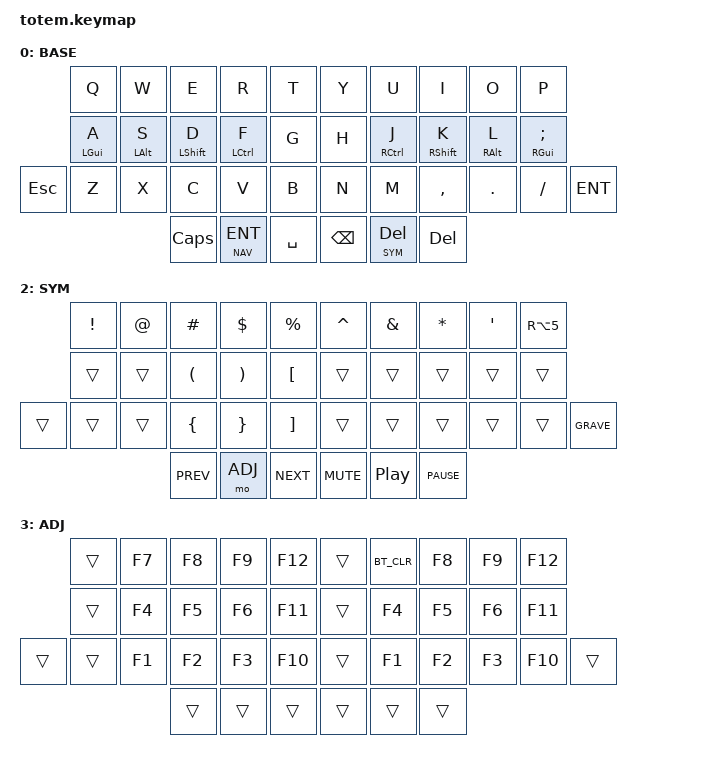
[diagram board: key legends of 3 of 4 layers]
//
//                                                        ▀▀▀▀▀     ▀▀▀▀▀          ▀▀█▀▀
//                                                        ▄▀▀▀▄  ▄  ▄▀▀▀▄  ▄  ▄▀▀▀▄  █  ▄▀▀▀▄
//                                                        █   █  █  █   █  █  █   █  █  █   █
//                                                         ▀▀▀   █   ▀▀▀   █   ▀▀▀   ▀   ▀▀▀
//                                                               █      ▄▄▄█▄▄▄    █   █  
//                                                               ▀      █  █  █     █▄█
//                                                             ▀▀▀▀▀    █  █  █      ▀
//                                                                      ▀  ▀  ▀
//
// ▄▄▄▄▄▄▄▄▄▄▄▄▄▄▄▄▄▄▄▄▄▄▄▄▄▄▄▄▄▄▄▄▄▄▄▄▄▄▄▄▄▄▄▄▄▄▄▄▄▄▄▄▄▄▄▄▄▄▄▄▄▄▄▄▄▄▄▄▄▄▄▄▄▄▄▄▄▄▄▄▄▄▄▄▄▄▄▄▄▄▄▄▄▄▄▄▄▄▄▄▄▄▄▄▄▄▄▄▄▄▄▄▄▄▄▄▄▄▄▄▄▄▄▄▄▄▄▄▄▄▄▄▄▄▄▄▄▄▄▄▄▄▄▄▄▄▄▄▄
       

#include <behaviors.dtsi>
#include <dt-bindings/zmk/keys.h>
#include <dt-bindings/zmk/bt.h>
#include <dt-bindings/zmk/outputs.h>

#define BASE 0
#define NAV  1
#define SYM  2
#define ADJ  3

&mt {
  quick-tap-ms = <100>;
  global-quick-tap;
  flavor = "tap-preferred";
  tapping-term-ms = <170>;
};

/ {
    combos {
            compatible = "zmk,combos";
            combo_esc {
                timeout-ms = <50>;
                key-positions = <0 1>;
                bindings = <&kp ESC>;
            };
    };

    macros {
        gif: gif {
            label = "giphy";
            compatible = "zmk,behavior-macro";
            #binding-cells = <0>;
            bindings
                = <&macro_press &kp LSHFT>
                , <&macro_tap &kp N2>
                , <&macro_release &kp LSHFT>
                , <&macro_tap &kp G &kp I &kp F>
                ;
        };
    };

        keymap {
                compatible = "zmk,keymap";
// ▄▄▄▄▄▄▄▄▄▄▄▄▄▄▄▄▄▄▄▄▄▄▄▄▄▄▄▄▄▄▄▄▄▄▄▄▄▄▄▄▄▄▄▄▄▄▄▄▄▄▄▄▄▄▄▄▄▄▄▄▄▄▄▄▄▄▄▄▄▄▄▄▄▄▄▄▄▄▄▄▄▄▄▄▄▄▄▄▄▄▄▄▄▄▄▄▄▄▄▄▄▄▄▄▄▄▄▄▄▄▄▄▄▄▄▄▄▄▄▄▄▄▄▄▄▄▄▄▄▄▄▄▄▄▄▄▄▄▄▄▄▄▄▄▄▄▄▄▄

                base_layer {
// ┏━━━━━━━━━━━━━━━━━━━━━━━━━━━━━━━━━━━━━━━┓
label= "BASE"                              ;
// ┗━━━━━━━━━━━━━━━━━━━━━━━━━━━━━━━━━━━━━━━┛
//             ┏━━━━━━━━━━━┳━━━━━━━━━━━┳━━━━━━━━━━━┳━━━━━━━━━━━┳━━━━━━━━━━━┓   ┏━━━━━━━━━━━┳━━━━━━━━━━━┳━━━━━━━━━━━┳━━━━━━━━━━━┳━━━━━━━━━━━┓
//             ┃     Q     ┃     W     ┃     E     ┃     R     ┃     T     ┃   ┃     Y     ┃     U     ┃     I     ┃     O     ┃     P     ┃
//             ┣━━━━━━━━━━━╋━━━━━━━━━━━╋━━━━━━━━━━━╋━━━━━━━━━━━╋━━━━━━━━━━━┫   ┣━━━━━━━━━━━╋━━━━━━━━━━━╋━━━━━━━━━━━╋━━━━━━━━━━━╋━━━━━━━━━━━┫
//             ┃     A     ┃     S     ┃     D     ┃     F     ┃     G     ┃   ┃     H     ┃     J     ┃     K     ┃     L     ┃     ;     ┃
// ┏━━━━━━━━━━━╋━━━━━━━━━━━╋━━━━━━━━━━━╋━━━━━━━━━━━╋━━━━━━━━━━━╋━━━━━━━━━━━┫   ┣━━━━━━━━━━━╋━━━━━━━━━━━╋━━━━━━━━━━━╋━━━━━━━━━━━╋━━━━━━━━━━━╋━━━━━━━━━━━┓
// ┃    ESC    ┃     Z     ┃     X     ┃     C     ┃     V     ┃     B     ┃   ┃     N     ┃     M     ┃     ,     ┃     .     ┃     /     ┃     '     ┃
// ┗━━━━━━━━━━━┻━━━━━━━━━━━┻━━━━━━━━━━━╋━━━━━━━━━━━╋━━━━━━━━━━━╋━━━━━━━━━━━┫   ┣━━━━━━━━━━━╋━━━━━━━━━━━╋━━━━━━━━━━━╋━━━━━━━━━━━┻━━━━━━━━━━━┻━━━━━━━━━━━┛
//                                     ┃    CAPS   ┃  ENT/NAV  ┃    SPC    ┃   ┃    BSPC   ┃ DEL/SYM   ┃   PSCRN   ┃
//                                     ┗━━━━━━━━━━━┻━━━━━━━━━━━┻━━━━━━━━━━━┛   ┗━━━━━━━━━━━┻━━━━━━━━━━━┻━━━━━━━━━━━┛
 bindings = <
// ╷           ╷           ╷           ╷           ╷           ╷           ╷   ╷           ╷           ╷           ╷           ╷           ╷           ╷

                &kp Q       &kp W       &kp E       &kp R       &kp T           &kp Y       &kp U       &kp I       &kp O       &kp P
                &mt LGUI A  &mt LALT S  &mt LSHFT D &mt LCTRL F &kp G           &kp H       &mt RCTRL J &mt RSHFT K &mt RALT L  &mt RGUI SEMI
    &kp ESC     &kp Z       &kp X       &kp C       &kp V       &kp B           &kp N       &kp M       &kp COMMA   &kp DOT     &kp FSLH    &kp ENT
                                        &kp CAPS    &lt NAV ENT &kp SPACE       &kp BSPC    &lt SYM DEL &kp DEL
                        >;
                };

// ▄▄▄▄▄▄▄▄▄▄▄▄▄▄▄▄▄▄▄▄▄▄▄▄▄▄▄▄▄▄▄▄▄▄▄▄▄▄▄▄▄▄▄▄▄▄▄▄▄▄▄▄▄▄▄▄▄▄▄▄▄▄▄▄▄▄▄▄▄▄▄▄▄▄▄▄▄▄▄▄▄▄▄▄▄▄▄▄▄▄▄▄▄▄▄▄▄▄▄▄▄▄▄▄▄▄▄▄▄▄▄▄▄▄▄▄▄▄▄▄▄▄▄▄▄▄▄▄▄▄▄▄▄▄▄▄▄▄▄▄▄▄▄▄▄▄▄▄▄


                nav_layer {
// ┏━━━━━━━━━━━━━━━━━━━━━━━━━━━━━━━━━━━━━━━┓
label= "NAVI"                              ;
// ┗━━━━━━━━━━━━━━━━━━━━━━━━━━━━━━━━━━━━━━━┛

//             ┏━━━━━━━━━━━┳━━━━━━━━━━━┳━━━━━━━━━━━┳━━━━━━━━━━━┳━━━━━━━━━━━┓   ┏━━━━━━━━━━━┳━━━━━━━━━━━┳━━━━━━━━━━━┳━━━━━━━━━━━┳━━━━━━━━━━━┓
//             ┃     /     ┃     7     ┃     8     ┃     9     ┃     +     ┃   ┃   HOME    ┃  P DOWN   ┃   P UP    ┃    END    ┃           ┃
//             ┣━━━━━━━━━━━╋━━━━━━━━━━━╋━━━━━━━━━━━╋━━━━━━━━━━━╋━━━━━━━━━━━┫   ┣━━━━━━━━━━━╋━━━━━━━━━━━╋━━━━━━━━━━━╋━━━━━━━━━━━╋━━━━━━━━━━━┫
//             ┃     .     ┃     4     ┃     5     ┃     6     ┃     -     ┃   ┃   LEFT    ┃    DOWN   ┃     UP    ┃   RIGHT   ┃           ┃
// ┏━━━━━━━━━━━╋━━━━━━━━━━━╋━━━━━━━━━━━╋━━━━━━━━━━━╋━━━━━━━━━━━╋━━━━━━━━━━━┫   ┣━━━━━━━━━━━╋━━━━━━━━━━━╋━━━━━━━━━━━╋━━━━━━━━━━━╋━━━━━━━━━━━╋━━━━━━━━━━━┓
// ┃     =     ┃     0     ┃     1     ┃     2     ┃     3     ┃     *     ┃   ┃  RC(LEFT) ┃  RC(DOWN) ┃  RC(UP)   ┃ RC(RIGHT) ┃           ┃           ┃
// ┗━━━━━━━━━━━┻━━━━━━━━━━━┻━━━━━━━━━━━╋━━━━━━━━━━━╋━━━━━━━━━━━╋━━━━━━━━━━━┫   ┣━━━━━━━━━━━╋━━━━━━━━━━━╋━━━━━━━━━━━╋━━━━━━━━━━━┻━━━━━━━━━━━┻━━━━━━━━━━━┛
//                                     ┃  VOL DOWN ┃   TRANS   ┃  VOL UP   ┃   ┃           ┃    ADJ    ┃           ┃
//                                     ┗━━━━━━━━━━━┻━━━━━━━━━━━┻━━━━━━━━━━━┛   ┗━━━━━━━━━━━┻━━━━━━━━━━━┻━━━━━━━━━━━┛

 bindings = <
// ╷           ╷           ╷           ╷           ╷           ╷           ╷   ╷           ╷           ╷           ╷           ╷           ╷           ╷

                &kp FSLH    &kp N7      &kp N8      &kp N9      &kp KP_PLUS     &kp HOME    &kp PG_DN   &kp PG_UP   &kp END                
                &kp DOT     &kp N4      &kp N5      &kp N6      &kp KP_MINUS    &kp LEFT    &kp DOWN    &kp UP      &kp RIGHT              
    &kp EQUAL   &kp N0      &kp N1      &kp N2      &kp N3      &kp KP_MULTIPLY &kp RC(LEFT) &kp RC(DOWN) &kp RC(UP) &kp RC(RIGHT) &trans 
                                       &kp C_VOL_DN &trans      &kp C_VOL_UP    &trans      &mo ADJ     &trans      
                        >;
                };

// ▄▄▄▄▄▄▄▄▄▄▄▄▄▄▄▄▄▄▄▄▄▄▄▄▄▄▄▄▄▄▄▄▄▄▄▄▄▄▄▄▄▄▄▄▄▄▄▄▄▄▄▄▄▄▄▄▄▄▄▄▄▄▄▄▄▄▄▄▄▄▄▄▄▄▄▄▄▄▄▄▄▄▄▄▄▄▄▄▄▄▄▄▄▄▄▄▄▄▄▄▄▄▄▄▄▄▄▄▄▄▄▄▄▄▄▄▄▄▄▄▄▄▄▄▄▄▄▄▄▄▄▄▄▄▄▄▄▄▄▄▄▄▄▄▄▄▄▄▄


                sym_layer {
// ┏━━━━━━━━━━━━━━━━━━━━━━━━━━━━━━━━━━━━━━━┓
label= "SYM"                               ;
// ┗━━━━━━━━━━━━━━━━━━━━━━━━━━━━━━━━━━━━━━━┛    
//             ┏━━━━━━━━━━━┳━━━━━━━━━━━┳━━━━━━━━━━━┳━━━━━━━━━━━┳━━━━━━━━━━━┓   ┏━━━━━━━━━━━┳━━━━━━━━━━━┳━━━━━━━━━━━┳━━━━━━━━━━━┳━━━━━━━━━━━┓
//             ┃     !     ┃     @     ┃     #     ┃     $     ┃     %     ┃   ┃     ˆ     ┃     &     ┃     *     ┃     ~     ┃     €     ┃
//             ┣━━━━━━━━━━━╋━━━━━━━━━━━╋━━━━━━━━━━━╋━━━━━━━━━━━╋━━━━━━━━━━━┫   ┣━━━━━━━━━━━╋━━━━━━━━━━━╋━━━━━━━━━━━╋━━━━━━━━━━━╋━━━━━━━━━━━┫
//             ┃     \     ┃     -     ┃     (     ┃     )     ┃     [     ┃   ┃           ┃           ┃           ┃           ┃           ┃
// ┏━━━━━━━━━━━╋━━━━━━━━━━━╋━━━━━━━━━━━╋━━━━━━━━━━━╋━━━━━━━━━━━╋━━━━━━━━━━━┫   ┣━━━━━━━━━━━╋━━━━━━━━━━━╋━━━━━━━━━━━╋━━━━━━━━━━━╋━━━━━━━━━━━╋━━━━━━━━━━━┓
// ┃           ┃     |     ┃     _     ┃     {     ┃     }     ┃     ]     ┃   ┃           ┃           ┃           ┃           ┃           ┃     `     ┃
// ┗━━━━━━━━━━━┻━━━━━━━━━━━┻━━━━━━━━━━━╋━━━━━━━━━━━╋━━━━━━━━━━━╋━━━━━━━━━━━┫   ┣━━━━━━━━━━━╋━━━━━━━━━━━╋━━━━━━━━━━━╋━━━━━━━━━━━┻━━━━━━━━━━━┻━━━━━━━━━━━┛
//                                     ┃   PREV    ┃   ADJ     ┃   NEXT    ┃   ┃    MUTE   ┃   TRANS   ┃   PAUSE   ┃
//                                     ┗━━━━━━━━━━━┻━━━━━━━━━━━┻━━━━━━━━━━━┛   ┗━━━━━━━━━━━┻━━━━━━━━━━━┻━━━━━━━━━━━┛
 bindings = <
// ╷           ╷           ╷           ╷           ╷           ╷           ╷   ╷           ╷           ╷           ╷           ╷           ╷           ╷

                &kp EXCL    &kp AT      &kp HASH    &kp DLLR    &kp PRCNT       &kp CARET   &kp AMPS    &kp STAR   &kp SQT     &kp RA(N5)       
                &trans      &trans      &kp LPAR    &kp RPAR    &kp LBKT        &trans      &trans      &trans     &trans      &trans 
    &trans      &trans      &trans      &kp LBRC    &kp RBRC    &kp RBKT        &trans      &trans      &trans     &trans      &trans      GRAVE         
                                        &kp C_PREV  &mo ADJ     &kp C_NEXT      &kp C_MUTE  &kp C_PP    &kp C_PAUSE      
                        >;
                };

// ▄▄▄▄▄▄▄▄▄▄▄▄▄▄▄▄▄▄▄▄▄▄▄▄▄▄▄▄▄▄▄▄▄▄▄▄▄▄▄▄▄▄▄▄▄▄▄▄▄▄▄▄▄▄▄▄▄▄▄▄▄▄▄▄▄▄▄▄▄▄▄▄▄▄▄▄▄▄▄▄▄▄▄▄▄▄▄▄▄▄▄▄▄▄▄▄▄▄▄▄▄▄▄▄▄▄▄▄▄▄▄▄▄▄▄▄▄▄▄▄▄▄▄▄▄▄▄▄▄▄▄▄▄▄▄▄▄▄▄▄▄▄▄▄▄▄▄▄▄


                adjust_layer {
// ┏━━━━━━━━━━━━━━━━━━━━━━━━━━━━━━━━━━━━━━━┓
label= "ADJ"                               ;
// ┗━━━━━━━━━━━━━━━━━━━━━━━━━━━━━━━━━━━━━━━┛

//             ┏━━━━━━━━━━━┳━━━━━━━━━━━┳━━━━━━━━━━━┳━━━━━━━━━━━┳━━━━━━━━━━━┓   ┏━━━━━━━━━━━┳━━━━━━━━━━━┳━━━━━━━━━━━┳━━━━━━━━━━━┳━━━━━━━━━━━┓
//             ┃           ┃    F7     ┃    F8     ┃    F9     ┃    F12    ┃   ┃           ┃ BT CLEAR  ┃  OUT TOG  ┃  RESET    ┃ BOOTLOAD  ┃
//             ┣━━━━━━━━━━━╋━━━━━━━━━━━╋━━━━━━━━━━━╋━━━━━━━━━━━╋━━━━━━━━━━━┫   ┣━━━━━━━━━━━╋━━━━━━━━━━━╋━━━━━━━━━━━╋━━━━━━━━━━━╋━━━━━━━━━━━┫
//             ┃           ┃    F4     ┃    F5     ┃    F6     ┃    F11    ┃   ┃ BT NEXT   ┃   BT_4    ┃   BT_5    ┃   BT_6    ┃           ┃
// ┏━━━━━━━━━━━╋━━━━━━━━━━━╋━━━━━━━━━━━╋━━━━━━━━━━━╋━━━━━━━━━━━╋━━━━━━━━━━━┫   ┣━━━━━━━━━━━╋━━━━━━━━━━━╋━━━━━━━━━━━╋━━━━━━━━━━━╋━━━━━━━━━━━╋━━━━━━━━━━━┓
// ┃           ┃           ┃    F1     ┃    F2     ┃    F3     ┃    F10    ┃   ┃ BT PREV   ┃   BT_1    ┃   BT_2    ┃   BT_3    ┃           ┃           ┃
// ┗━━━━━━━━━━━┻━━━━━━━━━━━┻━━━━━━━━━━━╋━━━━━━━━━━━╋━━━━━━━━━━━╋━━━━━━━━━━━┫   ┣━━━━━━━━━━━╋━━━━━━━━━━━╋━━━━━━━━━━━╋━━━━━━━━━━━┻━━━━━━━━━━━┻━━━━━━━━━━━┛
//                                     ┃           ┃   TRANS   ┃           ┃   ┃           ┃   TRANS   ┃           ┃
//                                     ┗━━━━━━━━━━━┻━━━━━━━━━━━┻━━━━━━━━━━━┛   ┗━━━━━━━━━━━┻━━━━━━━━━━━┻━━━━━━━━━━━┛

 bindings = <
// ╷           ╷           ╷           ╷           ╷           ╷           ╷   ╷           ╷           ╷           ╷           ╷           ╷           ╷

                &trans      &kp F7      &kp F8      &kp F9      &kp F12         &trans      &kp BT_CLR  &kp F8      &kp F9      &kp F12
                &trans      &kp F4      &kp F5      &kp F6      &kp F11         &trans      &kp F4      &kp F5      &kp F6      &kp F11  
    &trans      &trans      &kp F1      &kp F2      &kp F3      &kp F10         &trans      &kp F1      &kp F2      &kp F3      &kp F10     &trans         
                                        &trans      &trans      &trans          &trans      &trans      &trans      
                        >;
                };
        };
};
